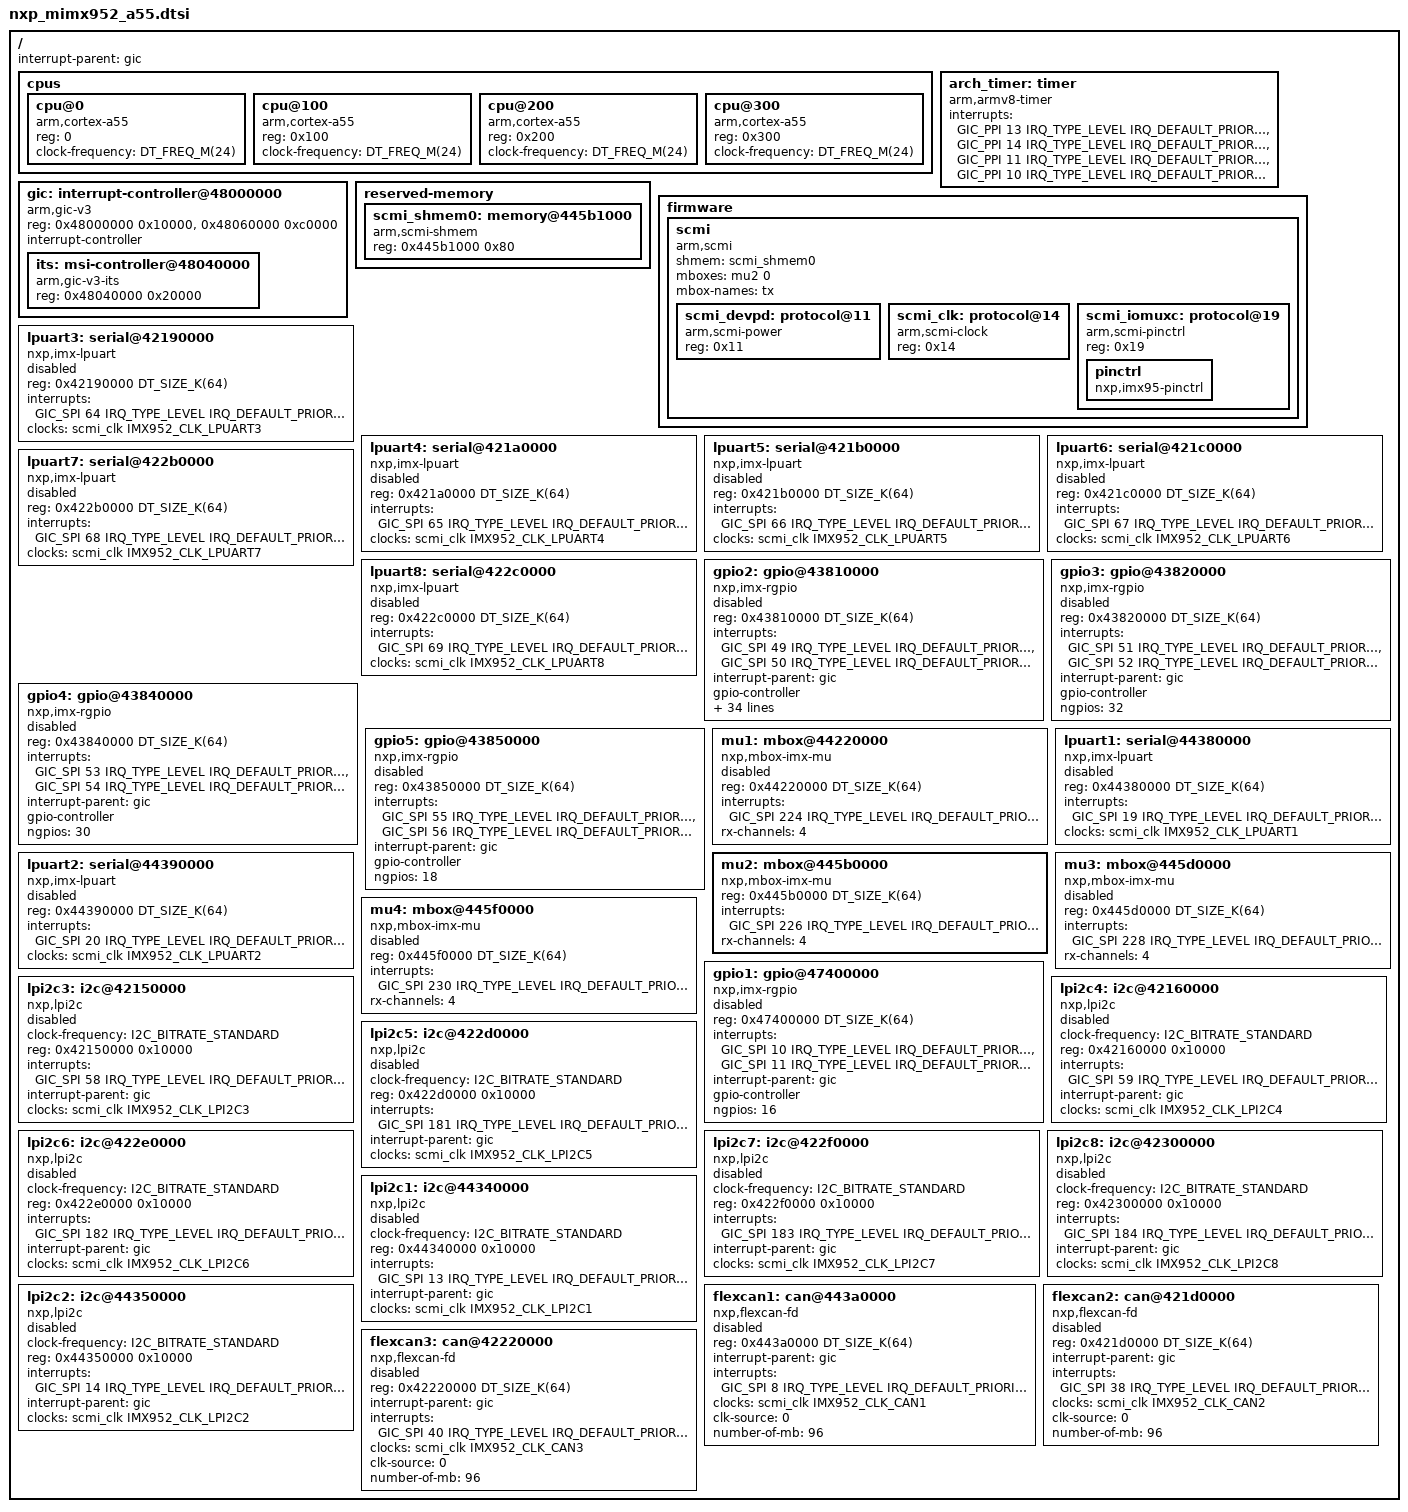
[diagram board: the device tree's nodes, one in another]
/*
 * SPDX-FileCopyrightText: Copyright 2026 NXP
 *
 * SPDX-License-Identifier: Apache-2.0
 */

#include <mem.h>
#include <freq.h>
#include <arm64/armv8-a.dtsi>
#include <zephyr/dt-bindings/i2c/i2c.h>
#include <zephyr/dt-bindings/clock/imx952_clock.h>
#include <zephyr/dt-bindings/interrupt-controller/arm-gic.h>
#include <zephyr/dt-bindings/gpio/gpio.h>

/ {
	#address-cells = <1>;
	#size-cells = <1>;
	interrupt-parent = <&gic>;

	cpus {
		#address-cells = <1>;
		#size-cells = <0>;

		cpu@0 {
			device_type = "cpu";
			compatible = "arm,cortex-a55";
			reg = <0>;
			clock-frequency = <DT_FREQ_M(24)>;
		};

		cpu@100 {
			device_type = "cpu";
			compatible = "arm,cortex-a55";
			reg = <0x100>;
			clock-frequency = <DT_FREQ_M(24)>;
		};

		cpu@200 {
			device_type = "cpu";
			compatible = "arm,cortex-a55";
			reg = <0x200>;
			clock-frequency = <DT_FREQ_M(24)>;
		};

		cpu@300 {
			device_type = "cpu";
			compatible = "arm,cortex-a55";
			reg = <0x300>;
			clock-frequency = <DT_FREQ_M(24)>;
		};
	};

	arch_timer: timer {
		compatible = "arm,armv8-timer";
		interrupts = <GIC_PPI 13 IRQ_TYPE_LEVEL
			      IRQ_DEFAULT_PRIORITY>,
			     <GIC_PPI 14 IRQ_TYPE_LEVEL
			      IRQ_DEFAULT_PRIORITY>,
			     <GIC_PPI 11 IRQ_TYPE_LEVEL
			      IRQ_DEFAULT_PRIORITY>,
			     <GIC_PPI 10 IRQ_TYPE_LEVEL
			      IRQ_DEFAULT_PRIORITY>;
	};

	gic: interrupt-controller@48000000 {
		compatible = "arm,gic-v3", "arm,gic";
		reg = <0x48000000 0x10000>, /* GIC Dist */
		      <0x48060000 0xc0000>; /* GICR (RD_base + SGI_base) */
		interrupt-controller;
		#interrupt-cells = <4>;
		#address-cells = <1>;
		#size-cells = <1>;
		status = "okay";

		its: msi-controller@48040000 {
			compatible = "arm,gic-v3-its";
			reg = <0x48040000 0x20000>;
			status = "okay";
		};
	};

	reserved-memory {
		#address-cells = <1>;
		#size-cells = <1>;

		scmi_shmem0: memory@445b1000 {
			compatible = "arm,scmi-shmem";
			reg = <0x445b1000 0x80>;
		};
	};

	firmware {
		scmi {
			compatible = "arm,scmi";
			shmem = <&scmi_shmem0>;
			mboxes = <&mu2 0>;
			mbox-names = "tx";

			#address-cells = <1>;
			#size-cells = <0>;

			scmi_devpd: protocol@11 {
				compatible = "arm,scmi-power";
				reg = <0x11>;
				#power-domain-cells = <1>;
			};

			scmi_clk: protocol@14 {
				compatible = "arm,scmi-clock";
				reg = <0x14>;
				#clock-cells = <1>;
			};

			scmi_iomuxc: protocol@19 {
				compatible = "arm,scmi-pinctrl";
				reg = <0x19>;

				pinctrl: pinctrl {
					compatible = "nxp,imx95-pinctrl", "nxp,imx93-pinctrl";
				};
			};
		};
	};

	lpuart3: serial@42190000 {
		compatible = "nxp,imx-lpuart", "nxp,lpuart";
		reg = <0x42190000 DT_SIZE_K(64)>;
		interrupts = <GIC_SPI 64 IRQ_TYPE_LEVEL IRQ_DEFAULT_PRIORITY>;
		interrupt-names = "irq_0";
		clocks = <&scmi_clk IMX952_CLK_LPUART3>;
		status = "disabled";
	};

	lpuart4: serial@421a0000 {
		compatible = "nxp,imx-lpuart", "nxp,lpuart";
		reg = <0x421a0000 DT_SIZE_K(64)>;
		interrupts = <GIC_SPI 65 IRQ_TYPE_LEVEL IRQ_DEFAULT_PRIORITY>;
		interrupt-names = "irq_0";
		clocks = <&scmi_clk IMX952_CLK_LPUART4>;
		status = "disabled";
	};

	lpuart5: serial@421b0000 {
		compatible = "nxp,imx-lpuart", "nxp,lpuart";
		reg = <0x421b0000 DT_SIZE_K(64)>;
		interrupts = <GIC_SPI 66 IRQ_TYPE_LEVEL IRQ_DEFAULT_PRIORITY>;
		interrupt-names = "irq_0";
		clocks = <&scmi_clk IMX952_CLK_LPUART5>;
		status = "disabled";
	};

	lpuart6: serial@421c0000 {
		compatible = "nxp,imx-lpuart", "nxp,lpuart";
		reg = <0x421c0000 DT_SIZE_K(64)>;
		interrupts = <GIC_SPI 67 IRQ_TYPE_LEVEL IRQ_DEFAULT_PRIORITY>;
		interrupt-names = "irq_0";
		clocks = <&scmi_clk IMX952_CLK_LPUART6>;
		status = "disabled";
	};

	lpuart7: serial@422b0000 {
		compatible = "nxp,imx-lpuart", "nxp,lpuart";
		reg = <0x422b0000 DT_SIZE_K(64)>;
		interrupts = <GIC_SPI 68 IRQ_TYPE_LEVEL IRQ_DEFAULT_PRIORITY>;
		interrupt-names = "irq_0";
		clocks = <&scmi_clk IMX952_CLK_LPUART7>;
		status = "disabled";
	};

	lpuart8: serial@422c0000 {
		compatible = "nxp,imx-lpuart", "nxp,lpuart";
		reg = <0x422c0000 DT_SIZE_K(64)>;
		interrupts = <GIC_SPI 69 IRQ_TYPE_LEVEL IRQ_DEFAULT_PRIORITY>;
		interrupt-names = "irq_0";
		clocks = <&scmi_clk IMX952_CLK_LPUART8>;
		status = "disabled";
	};

	gpio2: gpio@43810000 {
		compatible = "nxp,imx-rgpio";
		reg = <0x43810000 DT_SIZE_K(64)>;
		interrupts = <GIC_SPI 49 IRQ_TYPE_LEVEL IRQ_DEFAULT_PRIORITY>,
			     <GIC_SPI 50 IRQ_TYPE_LEVEL IRQ_DEFAULT_PRIORITY>;
		interrupt-names = "irq_0", "irq_1";
		interrupt-parent = <&gic>;
		gpio-controller;
		#gpio-cells = <2>;
		ngpios = <32>;
		status = "disabled";
	};

	gpio3: gpio@43820000 {
		compatible = "nxp,imx-rgpio";
		reg = <0x43820000 DT_SIZE_K(64)>;
		interrupts = <GIC_SPI 51 IRQ_TYPE_LEVEL IRQ_DEFAULT_PRIORITY>,
			     <GIC_SPI 52 IRQ_TYPE_LEVEL IRQ_DEFAULT_PRIORITY>;
		interrupt-names = "irq_0", "irq_1";
		interrupt-parent = <&gic>;
		gpio-controller;
		#gpio-cells = <2>;
		ngpios = <32>;
		status = "disabled";
	};

	gpio4: gpio@43840000 {
		compatible = "nxp,imx-rgpio";
		reg = <0x43840000 DT_SIZE_K(64)>;
		interrupts = <GIC_SPI 53 IRQ_TYPE_LEVEL IRQ_DEFAULT_PRIORITY>,
			     <GIC_SPI 54 IRQ_TYPE_LEVEL IRQ_DEFAULT_PRIORITY>;
		interrupt-names = "irq_0", "irq_1";
		interrupt-parent = <&gic>;
		gpio-controller;
		#gpio-cells = <2>;
		ngpios = <30>;
		status = "disabled";
	};

	gpio5: gpio@43850000 {
		compatible = "nxp,imx-rgpio";
		reg = <0x43850000 DT_SIZE_K(64)>;
		interrupts = <GIC_SPI 55 IRQ_TYPE_LEVEL IRQ_DEFAULT_PRIORITY>,
			     <GIC_SPI 56 IRQ_TYPE_LEVEL IRQ_DEFAULT_PRIORITY>;
		interrupt-names = "irq_0", "irq_1";
		interrupt-parent = <&gic>;
		gpio-controller;
		#gpio-cells = <2>;
		ngpios = <18>;
		status = "disabled";
	};

	mu1: mbox@44220000 {
		compatible = "nxp,mbox-imx-mu";
		reg = <0x44220000 DT_SIZE_K(64)>;
		interrupts = <GIC_SPI 224 IRQ_TYPE_LEVEL IRQ_DEFAULT_PRIORITY>;
		rx-channels = <4>;
		#mbox-cells = <1>;
		status = "disabled";
	};

	lpuart1: serial@44380000 {
		compatible = "nxp,imx-lpuart", "nxp,lpuart";
		reg = <0x44380000 DT_SIZE_K(64)>;
		interrupts = <GIC_SPI 19 IRQ_TYPE_LEVEL IRQ_DEFAULT_PRIORITY>;
		interrupt-names = "irq_0";
		clocks = <&scmi_clk IMX952_CLK_LPUART1>;
		status = "disabled";
	};

	lpuart2: serial@44390000 {
		compatible = "nxp,imx-lpuart", "nxp,lpuart";
		reg = <0x44390000 DT_SIZE_K(64)>;
		interrupts = <GIC_SPI 20 IRQ_TYPE_LEVEL IRQ_DEFAULT_PRIORITY>;
		interrupt-names = "irq_0";
		clocks = <&scmi_clk IMX952_CLK_LPUART2>;
		status = "disabled";
	};

	mu2: mbox@445b0000 {
		compatible = "nxp,mbox-imx-mu";
		reg = <0x445b0000 DT_SIZE_K(64)>;
		interrupts = <GIC_SPI 226 IRQ_TYPE_LEVEL IRQ_DEFAULT_PRIORITY>;
		rx-channels = <4>;
		#mbox-cells = <1>;
	};

	mu3: mbox@445d0000 {
		compatible = "nxp,mbox-imx-mu";
		reg = <0x445d0000 DT_SIZE_K(64)>;
		interrupts = <GIC_SPI 228 IRQ_TYPE_LEVEL IRQ_DEFAULT_PRIORITY>;
		rx-channels = <4>;
		#mbox-cells = <1>;
		status = "disabled";
	};

	mu4: mbox@445f0000 {
		compatible = "nxp,mbox-imx-mu";
		reg = <0x445f0000 DT_SIZE_K(64)>;
		interrupts = <GIC_SPI 230 IRQ_TYPE_LEVEL IRQ_DEFAULT_PRIORITY>;
		rx-channels = <4>;
		#mbox-cells = <1>;
		status = "disabled";
	};

	gpio1: gpio@47400000 {
		compatible = "nxp,imx-rgpio";
		reg = <0x47400000 DT_SIZE_K(64)>;
		interrupts = <GIC_SPI 10 IRQ_TYPE_LEVEL IRQ_DEFAULT_PRIORITY>,
			     <GIC_SPI 11 IRQ_TYPE_LEVEL IRQ_DEFAULT_PRIORITY>;
		interrupt-names = "irq_0", "irq_1";
		interrupt-parent = <&gic>;
		gpio-controller;
		#gpio-cells = <2>;
		ngpios = <16>;
		status = "disabled";
	};

	lpi2c3: i2c@42150000 {
		compatible = "nxp,lpi2c";
		clock-frequency = <I2C_BITRATE_STANDARD>;
		#address-cells = <1>;
		#size-cells = <0>;
		reg = <0x42150000 0x10000>;
		interrupts = <GIC_SPI 58 IRQ_TYPE_LEVEL IRQ_DEFAULT_PRIORITY>;
		interrupt-names = "irq_0";
		interrupt-parent = <&gic>;
		clocks = <&scmi_clk IMX952_CLK_LPI2C3>;
		status = "disabled";
	};

	lpi2c4: i2c@42160000 {
		compatible = "nxp,lpi2c";
		clock-frequency = <I2C_BITRATE_STANDARD>;
		#address-cells = <1>;
		#size-cells = <0>;
		reg = <0x42160000 0x10000>;
		interrupts = <GIC_SPI 59 IRQ_TYPE_LEVEL IRQ_DEFAULT_PRIORITY>;
		interrupt-names = "irq_0";
		interrupt-parent = <&gic>;
		clocks = <&scmi_clk IMX952_CLK_LPI2C4>;
		status = "disabled";
	};

	lpi2c5: i2c@422d0000 {
		compatible = "nxp,lpi2c";
		clock-frequency = <I2C_BITRATE_STANDARD>;
		#address-cells = <1>;
		#size-cells = <0>;
		reg = <0x422d0000 0x10000>;
		interrupts = <GIC_SPI 181 IRQ_TYPE_LEVEL IRQ_DEFAULT_PRIORITY>;
		interrupt-names = "irq_0";
		interrupt-parent = <&gic>;
		clocks = <&scmi_clk IMX952_CLK_LPI2C5>;
		status = "disabled";
	};

	lpi2c6: i2c@422e0000 {
		compatible = "nxp,lpi2c";
		clock-frequency = <I2C_BITRATE_STANDARD>;
		#address-cells = <1>;
		#size-cells = <0>;
		reg = <0x422e0000 0x10000>;
		interrupts = <GIC_SPI 182 IRQ_TYPE_LEVEL IRQ_DEFAULT_PRIORITY>;
		interrupt-names = "irq_0";
		interrupt-parent = <&gic>;
		clocks = <&scmi_clk IMX952_CLK_LPI2C6>;
		status = "disabled";
	};

	lpi2c7: i2c@422f0000 {
		compatible = "nxp,lpi2c";
		clock-frequency = <I2C_BITRATE_STANDARD>;
		#address-cells = <1>;
		#size-cells = <0>;
		reg = <0x422f0000 0x10000>;
		interrupts = <GIC_SPI 183 IRQ_TYPE_LEVEL IRQ_DEFAULT_PRIORITY>;
		interrupt-names = "irq_0";
		interrupt-parent = <&gic>;
		clocks = <&scmi_clk IMX952_CLK_LPI2C7>;
		status = "disabled";
	};

	lpi2c8: i2c@42300000 {
		compatible = "nxp,lpi2c";
		clock-frequency = <I2C_BITRATE_STANDARD>;
		#address-cells = <1>;
		#size-cells = <0>;
		reg = <0x42300000 0x10000>;
		interrupts = <GIC_SPI 184 IRQ_TYPE_LEVEL IRQ_DEFAULT_PRIORITY>;
		interrupt-names = "irq_0";
		interrupt-parent = <&gic>;
		clocks = <&scmi_clk IMX952_CLK_LPI2C8>;
		status = "disabled";
	};

	lpi2c1: i2c@44340000 {
		compatible = "nxp,lpi2c";
		clock-frequency = <I2C_BITRATE_STANDARD>;
		#address-cells = <1>;
		#size-cells = <0>;
		reg = <0x44340000 0x10000>;
		interrupts = <GIC_SPI 13 IRQ_TYPE_LEVEL IRQ_DEFAULT_PRIORITY>;
		interrupt-names = "irq_0";
		interrupt-parent = <&gic>;
		clocks = <&scmi_clk IMX952_CLK_LPI2C1>;
		status = "disabled";
	};

	lpi2c2: i2c@44350000 {
		compatible = "nxp,lpi2c";
		clock-frequency = <I2C_BITRATE_STANDARD>;
		#address-cells = <1>;
		#size-cells = <0>;
		reg = <0x44350000 0x10000>;
		interrupts = <GIC_SPI 14 IRQ_TYPE_LEVEL IRQ_DEFAULT_PRIORITY>;
		interrupt-names = "irq_0";
		interrupt-parent = <&gic>;
		clocks = <&scmi_clk IMX952_CLK_LPI2C2>;
		status = "disabled";
	};

	flexcan1: can@443a0000 {
		compatible = "nxp,flexcan-fd", "nxp,flexcan";
		reg = <0x443a0000 DT_SIZE_K(64)>;
		interrupt-parent = <&gic>;
		interrupts = <GIC_SPI 8 IRQ_TYPE_LEVEL IRQ_DEFAULT_PRIORITY>;
		interrupt-names = "common";
		clocks = <&scmi_clk IMX952_CLK_CAN1>;
		clock-names = "clksrc0";
		clk-source = <0>;
		number-of-mb = <96>;
		status = "disabled";
	};

	flexcan2: can@421d0000 {
		compatible = "nxp,flexcan-fd", "nxp,flexcan";
		reg = <0x421d0000 DT_SIZE_K(64)>;
		interrupt-parent = <&gic>;
		interrupts = <GIC_SPI 38 IRQ_TYPE_LEVEL IRQ_DEFAULT_PRIORITY>;
		interrupt-names = "common";
		clocks = <&scmi_clk IMX952_CLK_CAN2>;
		clock-names = "clksrc0";
		clk-source = <0>;
		number-of-mb = <96>;
		status = "disabled";
	};

	flexcan3: can@42220000 {
		compatible = "nxp,flexcan-fd", "nxp,flexcan";
		reg = <0x42220000 DT_SIZE_K(64)>;
		interrupt-parent = <&gic>;
		interrupts = <GIC_SPI 40 IRQ_TYPE_LEVEL IRQ_DEFAULT_PRIORITY>;
		interrupt-names = "common";
		clocks = <&scmi_clk IMX952_CLK_CAN3>;
		clock-names = "clksrc0";
		clk-source = <0>;
		number-of-mb = <96>;
		status = "disabled";
	};
};

/*
 * GPIO pinmux options. These options define the pinmux settings
 * for GPIO ports on the package, so that the GPIO driver can
 * select GPIO mux options during GPIO configuration.
 */

&gpio2 {
	pinmux = <&iomuxc_gpio_io00_gpio_io_bit_gpio2_io_bit0>,
		 <&iomuxc_gpio_io01_gpio_io_bit_gpio2_io_bit1>,
		 <&iomuxc_gpio_io02_gpio_io_bit_gpio2_io_bit2>,
		 <&iomuxc_gpio_io03_gpio_io_bit_gpio2_io_bit3>,
		 <&iomuxc_gpio_io04_gpio_io_bit_gpio2_io_bit4>,
		 <&iomuxc_gpio_io05_gpio_io_bit_gpio2_io_bit5>,
		 <&iomuxc_gpio_io06_gpio_io_bit_gpio2_io_bit6>,
		 <&iomuxc_gpio_io07_gpio_io_bit_gpio2_io_bit7>,
		 <&iomuxc_gpio_io08_gpio_io_bit_gpio2_io_bit8>,
		 <&iomuxc_gpio_io09_gpio_io_bit_gpio2_io_bit9>,
		 <&iomuxc_gpio_io10_gpio_io_bit_gpio2_io_bit10>,
		 <&iomuxc_gpio_io11_gpio_io_bit_gpio2_io_bit11>,
		 <&iomuxc_gpio_io12_gpio_io_bit_gpio2_io_bit12>,
		 <&iomuxc_gpio_io13_gpio_io_bit_gpio2_io_bit13>,
		 <&iomuxc_gpio_io14_gpio_io_bit_gpio2_io_bit14>,
		 <&iomuxc_gpio_io15_gpio_io_bit_gpio2_io_bit15>,
		 <&iomuxc_gpio_io16_gpio_io_bit_gpio2_io_bit16>,
		 <&iomuxc_gpio_io17_gpio_io_bit_gpio2_io_bit17>,
		 <&iomuxc_gpio_io18_gpio_io_bit_gpio2_io_bit18>,
		 <&iomuxc_gpio_io19_gpio_io_bit_gpio2_io_bit19>,
		 <&iomuxc_gpio_io20_gpio_io_bit_gpio2_io_bit20>,
		 <&iomuxc_gpio_io21_gpio_io_bit_gpio2_io_bit21>,
		 <&iomuxc_gpio_io22_gpio_io_bit_gpio2_io_bit22>,
		 <&iomuxc_gpio_io23_gpio_io_bit_gpio2_io_bit23>,
		 <&iomuxc_gpio_io24_gpio_io_bit_gpio2_io_bit24>,
		 <&iomuxc_gpio_io25_gpio_io_bit_gpio2_io_bit25>,
		 <&iomuxc_gpio_io26_gpio_io_bit_gpio2_io_bit26>,
		 <&iomuxc_gpio_io27_gpio_io_bit_gpio2_io_bit27>,
		 <&iomuxc_gpio_io28_gpio_io_bit_gpio2_io_bit28>,
		 <&iomuxc_gpio_io29_gpio_io_bit_gpio2_io_bit29>,
		 <&iomuxc_gpio_io30_gpio_io_bit_gpio2_io_bit30>,
		 <&iomuxc_gpio_io31_gpio_io_bit_gpio2_io_bit31>;
};
